BO_ 165 Motor_Position_Information: 8
	SG_ Motor_Speed : 16|16@1- (1, 0) [-32768|32767] "rpm"

BO_ 162 Temperature_3: 8
	SG_ Motor_Temperature: 32|16@1- (0.1, 0) [-3276.8|3276.7] "Celsius"
	SG_ Coolant_Temperature: 0|16@1- (0.1, 0) [-3276.8|3276.7] "Celsius"

BO_ 166 Current_Information: 8
	SG_ DC_Bus_Current: 48|16@1- (0.1, 0) [-3276.8|3276.7] "Amps"

BO_ 167 Voltage_Information: 8
	SG_ DC_Bus_Voltage: 0|16@1- (0.1, 0) [-3276.8|3276.7] "Volts"
	SG_ Output_Voltage: 16|16@1- (0.1, 0) [-3276.8|3276.7] "Volts"

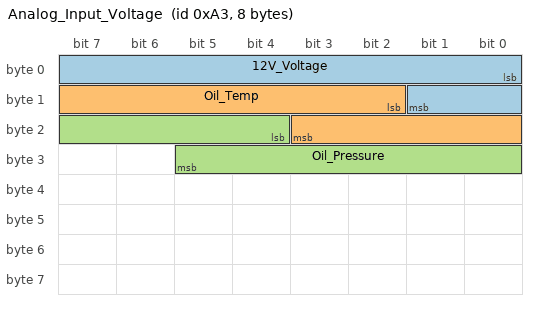
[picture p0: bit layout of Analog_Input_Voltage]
BO_ 163 Analog_Input_Voltage: 8
	SG_ 12V_Voltage: 0|10@1- (0.01, 0) [-327.68|327.67] "Volts"
	SG_ Oil_Temp: 10|10@1- (0.01, 0) [-327.68|327.67] "Volts"
	SG_ Oil_Pressure: 20|10@1- (0.01, 0) [-327.68|327.67] "Volts"
